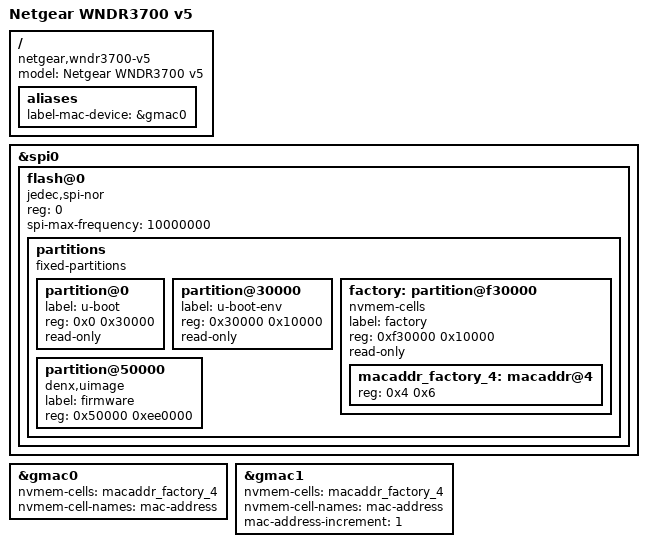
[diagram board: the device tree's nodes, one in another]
// SPDX-License-Identifier: GPL-2.0-only

#include "mt7621_netgear_sercomm_ayx.dtsi"

/ {
	compatible = "netgear,wndr3700-v5", "mediatek,mt7621-soc";
	model = "Netgear WNDR3700 v5";

	aliases {
		label-mac-device = &gmac0;
	};
};

&spi0 {
	status = "okay";

	flash@0 {
		compatible = "jedec,spi-nor";
		reg = <0>;
		spi-max-frequency = <10000000>;

		partitions {
			compatible = "fixed-partitions";
			#address-cells = <1>;
			#size-cells = <1>;

			partition@0 {
				label = "u-boot";
				reg = <0x0 0x30000>;
				read-only;
			};

			partition@30000 {
				label = "u-boot-env";
				reg = <0x30000 0x10000>;
				read-only;
			};

			factory: partition@f30000 {
				label = "factory";
				reg = <0xf30000 0x10000>;
				read-only;
			};

			partition@50000 {
				compatible = "denx,uimage";
				label = "firmware";
				reg = <0x50000 0xee0000>;
			};
		};
	};
};

&gmac0 {
	nvmem-cells = <&macaddr_factory_4>;
	nvmem-cell-names = "mac-address";
};

&gmac1 {
	nvmem-cells = <&macaddr_factory_4>;
	nvmem-cell-names = "mac-address";
	mac-address-increment = <1>;
};

&factory {
	compatible = "nvmem-cells";
	#address-cells = <1>;
	#size-cells = <1>;

	macaddr_factory_4: macaddr@4 {
		reg = <0x4 0x6>;
	};
};
